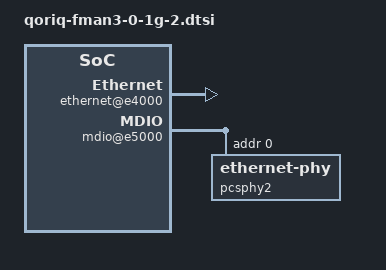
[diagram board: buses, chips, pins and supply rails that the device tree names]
// SPDX-License-Identifier: (GPL-2.0+ OR BSD-3-Clause)
/*
 * QorIQ FMan v3 1g port #2 device tree
 *
 * Copyright 2012-2015 Freescale Semiconductor Inc.
 *
 */

fman@1a00000 {
	fman0_rx_0x0a: port@8a000 {
		cell-index = <0xa>;
		compatible = "fsl,fman-v3-port-rx";
		reg = <0x8a000 0x1000>;
	};

	fman0_tx_0x2a: port@aa000 {
		cell-index = <0x2a>;
		compatible = "fsl,fman-v3-port-tx";
		reg = <0xaa000 0x1000>;
	};

	ethernet@e4000 {
		cell-index = <2>;
		compatible = "fsl,fman-memac";
		reg = <0xe4000 0x1000>;
		fsl,fman-ports = <&fman0_rx_0x0a &fman0_tx_0x2a>;
		ptp-timer = <&ptp_timer0>;
		pcsphy-handle = <&pcsphy2>;
		pcs-handle = <&pcsphy2>;
	};

	mdio@e5000 {
		#address-cells = <1>;
		#size-cells = <0>;
		compatible = "fsl,fman-memac-mdio";
		reg = <0xe5000 0x1000>;

		pcsphy2: ethernet-phy@0 {
			reg = <0x0>;
		};
	};
};
